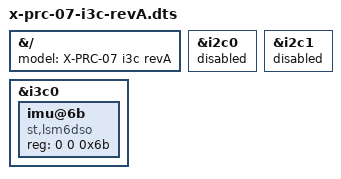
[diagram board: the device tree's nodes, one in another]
// SPDX-License-Identifier: GPL-2.0
/*
 * dts file for Xilinx ZynqMP VN-P-B2197 (Tenzing2) X-PRC-07 RevA with I3C enabled
 *
 * (C) Copyright 2022, Advanced Micro Devices, Inc.
 *
 * Jay Buddhabhatti <jay.buddhabhatti@amd.com>;
 */

#include "x-prc-07-revA.dts"

&{/} {
	model = "X-PRC-07 i3c revA";
};

&i2c0 {
	status = "disabled";
};

&i2c1 {
	status = "disabled";
};

&i3c0 {
	status = "okay";
	#address-cells = <3>;
	#size-cells = <0>;

	/* check maximum frequency from datasheet */
	imu@6b { /* u120 */
		compatible = "st,lsm6dso";
		reg = <0 0 0x6b>;
	};
};
